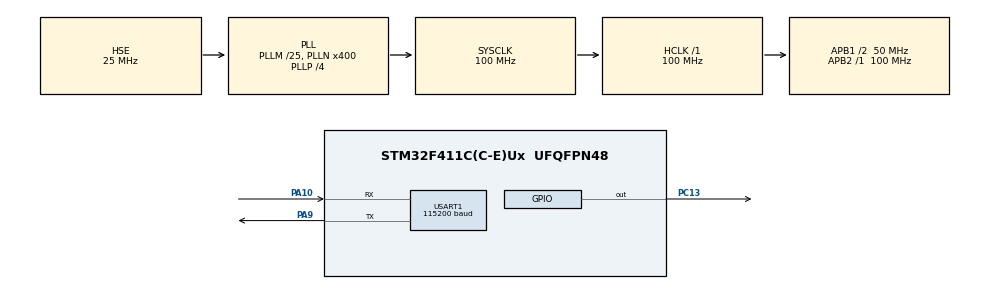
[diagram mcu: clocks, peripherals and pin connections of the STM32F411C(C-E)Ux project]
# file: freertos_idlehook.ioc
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Mcu.Family=STM32F4
Mcu.Name=STM32F411C(C-E)Ux
Mcu.Package=UFQFPN48
NVIC.PriorityGroup=NVIC_PRIORITYGROUP_4
NVIC.TIM1_UP_TIM10_IRQn=true\:0\:0\:false\:false\:true\:false\:true
NVIC.TimeBase=TIM1_UP_TIM10_IRQn
NVIC.TimeBaseIP=TIM1
PA10.Mode=Asynchronous
PA10.Signal=USART1_RX
PA13.Mode=Serial_Wire
PA13.Signal=SYS_JTMS-SWDIO
PA14.Mode=Serial_Wire
PA14.Signal=SYS_JTCK-SWCLK
PA9.Mode=Asynchronous
PA9.Signal=USART1_TX
PB3.Signal=SYS_JTDO-SWO
PC13-ANTI_TAMP.Signal=GPIO_Output
PH0\ -\ OSC_IN.Mode=HSE-External-Oscillator
PH0\ -\ OSC_IN.Signal=RCC_OSC_IN
PH1\ -\ OSC_OUT.Mode=HSE-External-Oscillator
PH1\ -\ OSC_OUT.Signal=RCC_OSC_OUT
ProjectManager.HeapSize=0x200
ProjectManager.StackSize=0x400
ProjectManager.TargetToolchain=STM32CubeIDE
RCC.48MHZClocksFreq_Value=100000000
RCC.AHBFreq_Value=100000000
RCC.APB1CLKDivider=RCC_HCLK_DIV2
RCC.APB1Freq_Value=50000000
RCC.APB1TimFreq_Value=100000000
RCC.APB2Freq_Value=100000000
RCC.APB2TimFreq_Value=100000000
RCC.CortexFreq_Value=100000000
RCC.HCLKFreq_Value=100000000
RCC.HSE_VALUE=25000000
RCC.HSI_VALUE=16000000
RCC.LSE_VALUE=32768
RCC.PLLM=25
RCC.PLLN=400
RCC.PLLP=RCC_PLLP_DIV4
RCC.PLLSourceVirtual=RCC_PLLSOURCE_HSE
RCC.SYSCLKFreq_VALUE=100000000
RCC.SYSCLKSource=RCC_SYSCLKSOURCE_PLLCLK
RCC.VCOOutputFreq_Value=400000000
USART1.BaudRate=115200
USART1.VirtualMode=VM_ASYNC
VP_SYS_VS_tim1.Mode=TIM1
board=custom

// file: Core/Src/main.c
/* USER CODE BEGIN Header */
// Weact v1.3 STM32F411CEU6
// Demonstrate use of idle hook to send the cpu to sleep when no tasks are running,
// it will wake up on next systick interrupt. Useful for saving power.

/* USER CODE END Header */

#include "main.h"

/* USER CODE BEGIN Includes */
#include <stdio.h>
#include <stdint.h>
#include <string.h>

#include "FreeRTOS.h"
#include "task.h"
/* USER CODE END Includes */

UART_HandleTypeDef huart1;

void SystemClock_Config(void);
static void MX_GPIO_Init(void);
static void MX_USART1_UART_Init(void);
/* USER CODE BEGIN PFP */
void vTask1_handler(void* pParams);
void vTask2_handler(void* pParams);
void printMsg(char *format,...);

/* USER CODE END PFP */

/* USER CODE BEGIN 0 */
TaskHandle_t xTaskHandle1 = NULL;
TaskHandle_t xTaskHandle2 = NULL;

void printMsg(char *format,...){
	char str[80];
	va_list args;
	va_start(args, format);
	vsprintf(str, format,args);
	HAL_UART_Transmit(&huart1, (uint8_t *)str, strlen(str),HAL_MAX_DELAY);
	va_end(args);
 }

/* USER CODE END 0 */

int main(void)
{
  /* USER CODE BEGIN 1 */
  DWT->CTRL |= (1 << 0); // enable CYCCNT for SystemView

  /* USER CODE END 1 */

  /* MCU Configuration--------------------------------------------------------*/

  /* Reset of all peripherals, Initializes the Flash interface and the Systick. */
  HAL_Init();

  /* Configure the system clock */
  SystemClock_Config();

  /* USER CODE BEGIN SysInit */
  HAL_RCC_DeInit(); // 16 MHz HSI
  SystemCoreClockUpdate();
  //HAL_Delay(50); // leave this here so that JLink/STlink can connect to cpu after reset

  /* USER CODE END SysInit */

  /* Initialize all configured peripherals */
  MX_GPIO_Init();
  MX_USART1_UART_Init();
  /* USER CODE BEGIN 2 */
  printMsg("SystemCoreClock %lu\r\n", SystemCoreClock);

  SEGGER_SYSVIEW_Conf();
  vSetVarulMaxPRIGROUPValue();
  SEGGER_SYSVIEW_Start();

  xTaskCreate(vTask1_handler, "Task-1", configMINIMAL_STACK_SIZE, NULL, 2, &xTaskHandle1);
  xTaskCreate(vTask2_handler, "Task-2", configMINIMAL_STACK_SIZE, NULL, 2, &xTaskHandle2);

  vTaskStartScheduler();
  /* USER CODE END 2 */

  /* Infinite loop */
  /* USER CODE BEGIN WHILE */
  int counter = 0;
  while (1)
  {
    /* USER CODE END WHILE */

    /* USER CODE BEGIN 3 */
	  // should never get here
	  HAL_GPIO_TogglePin(GPIOC, GPIO_PIN_13);
	  printMsg("main loop %d\r\n", counter++);
	  HAL_Delay(1000);
  }
  /* USER CODE END 3 */
}

void SystemClock_Config(void)
{
  RCC_OscInitTypeDef RCC_OscInitStruct = {0};
  RCC_ClkInitTypeDef RCC_ClkInitStruct = {0};

  /** Configure the main internal regulator output voltage
  */
  __HAL_RCC_PWR_CLK_ENABLE();
  __HAL_PWR_VOLTAGESCALING_CONFIG(PWR_REGULATOR_VOLTAGE_SCALE1);
  /** Initializes the CPU, AHB and APB busses clocks
  */
  RCC_OscInitStruct.OscillatorType = RCC_OSCILLATORTYPE_HSE;
  RCC_OscInitStruct.HSEState = RCC_HSE_ON;
  RCC_OscInitStruct.PLL.PLLState = RCC_PLL_ON;
  RCC_OscInitStruct.PLL.PLLSource = RCC_PLLSOURCE_HSE;
  RCC_OscInitStruct.PLL.PLLM = 25;
  RCC_OscInitStruct.PLL.PLLN = 400;
  RCC_OscInitStruct.PLL.PLLP = RCC_PLLP_DIV4;
  RCC_OscInitStruct.PLL.PLLQ = 4;
  if (HAL_RCC_OscConfig(&RCC_OscInitStruct) != HAL_OK)
  {
    Error_Handler();
  }
  /** Initializes the CPU, AHB and APB busses clocks
  */
  RCC_ClkInitStruct.ClockType = RCC_CLOCKTYPE_HCLK|RCC_CLOCKTYPE_SYSCLK
                              |RCC_CLOCKTYPE_PCLK1|RCC_CLOCKTYPE_PCLK2;
  RCC_ClkInitStruct.SYSCLKSource = RCC_SYSCLKSOURCE_PLLCLK;
  RCC_ClkInitStruct.AHBCLKDivider = RCC_SYSCLK_DIV1;
  RCC_ClkInitStruct.APB1CLKDivider = RCC_HCLK_DIV2;
  RCC_ClkInitStruct.APB2CLKDivider = RCC_HCLK_DIV1;

  if (HAL_RCC_ClockConfig(&RCC_ClkInitStruct, FLASH_LATENCY_3) != HAL_OK)
  {
    Error_Handler();
  }
}

static void MX_USART1_UART_Init(void)
{

  /* USER CODE BEGIN USART1_Init 1 */
  huart1.Init.BaudRate = 115200;

  /* USER CODE END USART1_Init 1 */
  huart1.Instance = USART1;
  huart1.Init.BaudRate = 115200;
  huart1.Init.WordLength = UART_WORDLENGTH_8B;
  huart1.Init.StopBits = UART_STOPBITS_1;
  huart1.Init.Parity = UART_PARITY_NONE;
  huart1.Init.Mode = UART_MODE_TX_RX;
  huart1.Init.HwFlowCtl = UART_HWCONTROL_NONE;
  huart1.Init.OverSampling = UART_OVERSAMPLING_16;
  if (HAL_UART_Init(&huart1) != HAL_OK)
  {
    Error_Handler();
  }

}

static void MX_GPIO_Init(void)
{
  GPIO_InitTypeDef GPIO_InitStruct = {0};

  /* GPIO Ports Clock Enable */
  __HAL_RCC_GPIOC_CLK_ENABLE();
  __HAL_RCC_GPIOH_CLK_ENABLE();
  __HAL_RCC_GPIOA_CLK_ENABLE();
  __HAL_RCC_GPIOB_CLK_ENABLE();

  /*Configure GPIO pin Output Level */
  HAL_GPIO_WritePin(GPIOC, GPIO_PIN_13, GPIO_PIN_RESET);

  /*Configure GPIO pin : PC13 */
  GPIO_InitStruct.Pin = GPIO_PIN_13;
  GPIO_InitStruct.Mode = GPIO_MODE_OUTPUT_PP;
  GPIO_InitStruct.Pull = GPIO_NOPULL;
  GPIO_InitStruct.Speed = GPIO_SPEED_FREQ_LOW;
  HAL_GPIO_Init(GPIOC, &GPIO_InitStruct);

}

/* USER CODE BEGIN 4 */
void vTask1_handler(void *params){
	while(1)	{
		printMsg("Status of the LED is: %d\r\n",HAL_GPIO_ReadPin(GPIOC,GPIO_PIN_13));
		vTaskDelay(pdMS_TO_TICKS(80));
		}
	}

void vTask2_handler(void *params){
	while(1)	{
		HAL_GPIO_TogglePin(GPIOC,GPIO_PIN_13);
		vTaskDelay(pdMS_TO_TICKS(50));
		}
	}

void vApplicationIdleHook(void){
	// Send the cpu to sleep using wfi, wake on interrupt (next Systick)
	// this is a good way to save power consumption when the cpu is not busy
	// i.e. when idle task runs

	// If you want to trace the transitions to/from Idle task in SystemView
	// comment this _WFI call.
	__WFI();
	}

/* USER CODE END 4 */

void HAL_TIM_PeriodElapsedCallback(TIM_HandleTypeDef *htim)
{
  if (htim->Instance == TIM1) {
    HAL_IncTick();
  }
}

void Error_Handler(void)
{
  /* USER CODE BEGIN Error_Handler_Debug */
  /* User can add his own implementation to report the HAL error return state */
	// toggle the board LED rapidly
	int counter = 0;
	while (1) {
		HAL_GPIO_TogglePin(GPIOC, GPIO_PIN_13);
		while (counter < 0x3FFFF) {counter++;}
		counter = 0;
		}
  /* USER CODE END Error_Handler_Debug */
}

/************************ (C) COPYRIGHT STMicroelectronics *****END OF FILE****/
